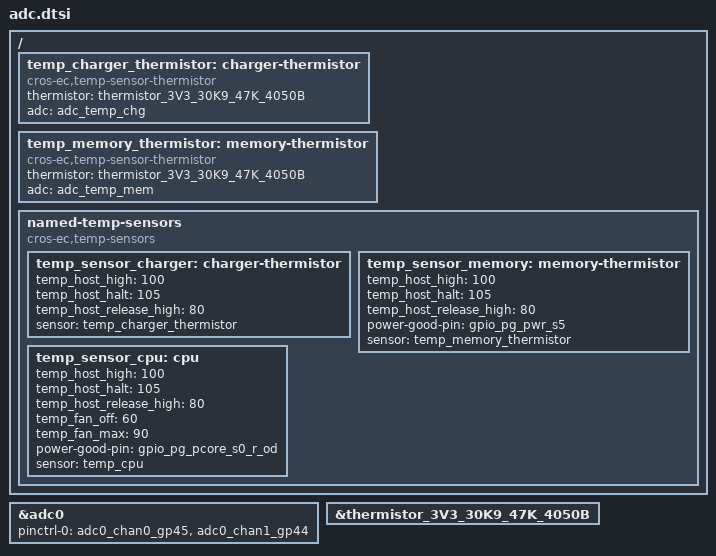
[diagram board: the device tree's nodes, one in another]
/* Copyright 2023 The ChromiumOS Authors
 * Use of this source code is governed by a BSD-style license that can be
 * found in the LICENSE file.
 */

#include <cros/thermistor/thermistor.dtsi>

/ {
	temp_charger_thermistor: charger-thermistor {
		compatible = "cros-ec,temp-sensor-thermistor";
		thermistor = <&thermistor_3V3_30K9_47K_4050B>;
		adc = <&adc_temp_chg>;
	};

	temp_memory_thermistor: memory-thermistor {
		compatible = "cros-ec,temp-sensor-thermistor";
		thermistor = <&thermistor_3V3_30K9_47K_4050B>;
		adc = <&adc_temp_mem>;
	};

	named-temp-sensors {
		compatible = "cros-ec,temp-sensors";
		temp_sensor_charger: charger-thermistor {
			temp_host_high = <100>;
			temp_host_halt = <105>;
			temp_host_release_high = <80>;
			sensor = <&temp_charger_thermistor>;
		};

		temp_sensor_memory: memory-thermistor {
			temp_host_high = <100>;
			temp_host_halt = <105>;
			temp_host_release_high = <80>;
			power-good-pin = <&gpio_pg_pwr_s5>;
			sensor = <&temp_memory_thermistor>;
		};

		temp_sensor_cpu: cpu {
			temp_host_high = <100>;
			temp_host_halt = <105>;
			temp_host_release_high = <80>;
			temp_fan_off = <60>;
			temp_fan_max = <90>;
			power-good-pin = <&gpio_pg_pcore_s0_r_od>;
			sensor = <&temp_cpu>;
		};

	};
};

&adc0 {
	status = "okay";
	pinctrl-0 = <&adc0_chan0_gp45
		     &adc0_chan1_gp44>;
	pinctrl-names = "default";
};

&thermistor_3V3_30K9_47K_4050B {
	status = "okay";
};
